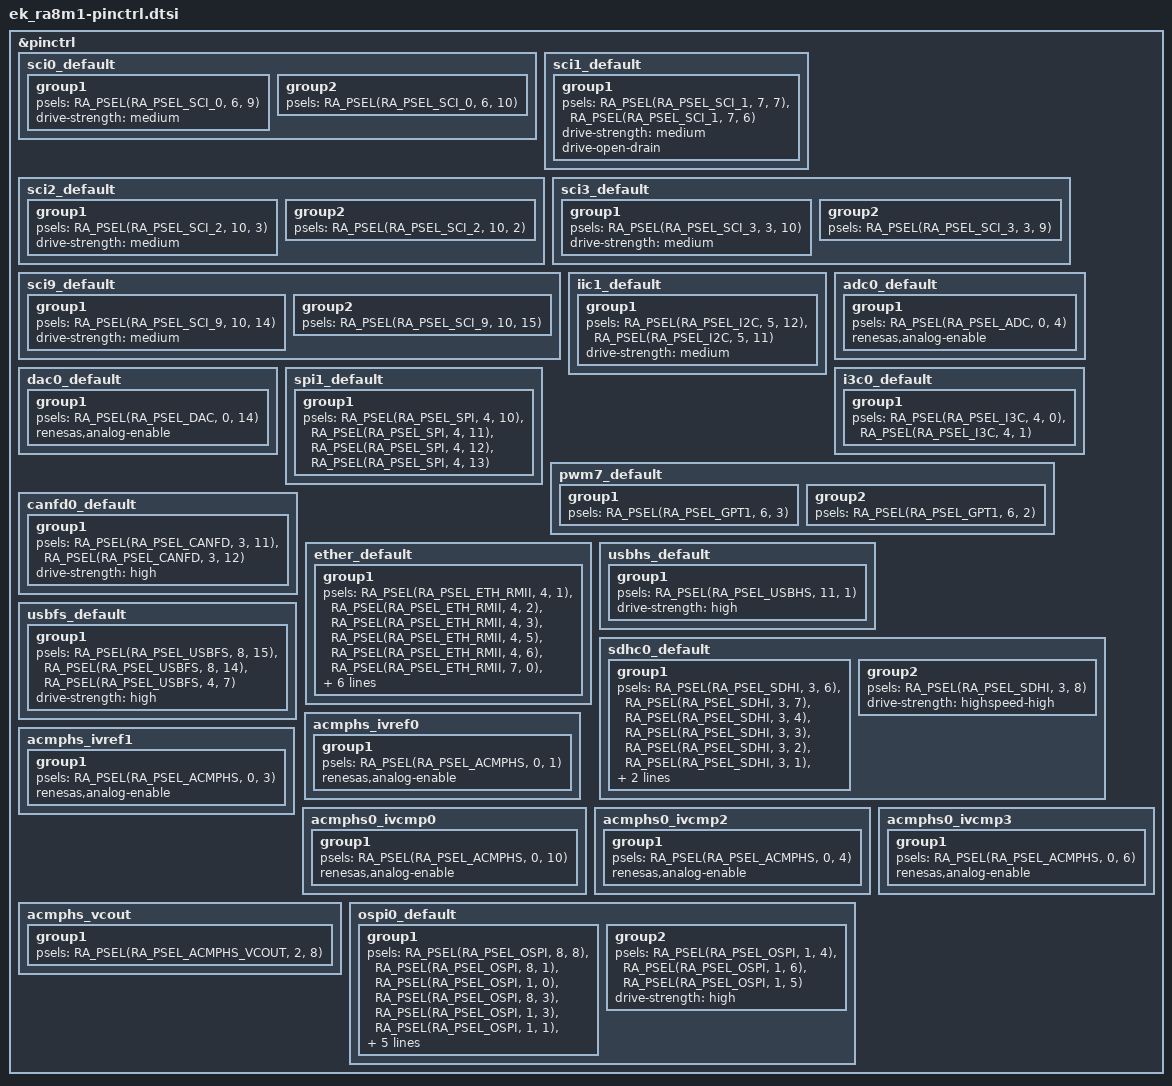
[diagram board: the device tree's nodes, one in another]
/*
 * Copyright (c) 2024-2025 Renesas Electronics Corporation
 * SPDX-License-Identifier: Apache-2.0
 */

&pinctrl {
	sci0_default: sci0_default {
		group1 {
			/* tx */
			psels = <RA_PSEL(RA_PSEL_SCI_0, 6, 9)>;
			drive-strength = "medium";
		};

		group2 {
			/* rx */
			psels = <RA_PSEL(RA_PSEL_SCI_0, 6, 10)>;
		};
	};

	sci1_default: sci1_default {
		group1 {
			/* sda scl */
			psels = <RA_PSEL(RA_PSEL_SCI_1, 7, 7)>, <RA_PSEL(RA_PSEL_SCI_1, 7, 6)>;
			drive-strength = "medium";
			drive-open-drain;
		};
	};

	sci2_default: sci2_default {
		group1 {
			/* tx */
			psels = <RA_PSEL(RA_PSEL_SCI_2, 10, 3)>;
			drive-strength = "medium";
		};

		group2 {
			/* rx */
			psels = <RA_PSEL(RA_PSEL_SCI_2, 10, 2)>;
		};
	};

	sci3_default: sci3_default {
		group1 {
			/* tx */
			psels = <RA_PSEL(RA_PSEL_SCI_3, 3, 10)>;
			drive-strength = "medium";
		};

		group2 {
			/* rx */
			psels = <RA_PSEL(RA_PSEL_SCI_3, 3, 9)>;
		};
	};

	sci9_default: sci9_default {
		group1 {
			/* tx */
			psels = <RA_PSEL(RA_PSEL_SCI_9, 10, 14)>;
			drive-strength = "medium";
		};

		group2 {
			/* rx */
			psels = <RA_PSEL(RA_PSEL_SCI_9, 10, 15)>;
		};
	};

	iic1_default: iic1_default {
		group1 {
			/* SCL1 SDA1*/
			psels = <RA_PSEL(RA_PSEL_I2C, 5, 12)>, <RA_PSEL(RA_PSEL_I2C, 5, 11)>;
			drive-strength = "medium";
		};
	};

	adc0_default: adc0_default {
		group1 {
			/* input */
			psels = <RA_PSEL(RA_PSEL_ADC, 0, 4)>;
			renesas,analog-enable;
		};
	};

	dac0_default: dac0_default {
		group1 {
			/* output */
			psels = <RA_PSEL(RA_PSEL_DAC, 0, 14)>;
			renesas,analog-enable;
		};
	};

	spi1_default: spi1_default {
		group1 {
			/* MISO MOSI RSPCK SSL*/
			psels = <RA_PSEL(RA_PSEL_SPI, 4, 10)>,
				<RA_PSEL(RA_PSEL_SPI, 4, 11)>,
				<RA_PSEL(RA_PSEL_SPI, 4, 12)>,
				<RA_PSEL(RA_PSEL_SPI, 4, 13)>;
		};
	};

	i3c0_default: i3c0_default {
		group1 {
			/* SCL SDA */
			psels = <RA_PSEL(RA_PSEL_I3C, 4, 0)>,
				<RA_PSEL(RA_PSEL_I3C, 4, 1)>;
		};
	};

	pwm7_default: pwm7_default {
		group1 {
			/* GTIOC7A */
			psels = <RA_PSEL(RA_PSEL_GPT1, 6, 3)>;
		};

		group2 {
			/* GTIOC7B */
			psels = <RA_PSEL(RA_PSEL_GPT1, 6, 2)>;
		};
	};

	canfd0_default: canfd0_default {
		group1 {
			/* CRX0 CTX0 */
			psels = <RA_PSEL(RA_PSEL_CANFD, 3, 11)>,
				<RA_PSEL(RA_PSEL_CANFD, 3, 12)>;
			drive-strength = "high";
		};
	};

	ether_default: ether_default {
		group1 {
			psels = <RA_PSEL(RA_PSEL_ETH_RMII, 4, 1)>, /* ET0_MDC */
				<RA_PSEL(RA_PSEL_ETH_RMII, 4, 2)>, /* ET0_MDIO */
				<RA_PSEL(RA_PSEL_ETH_RMII, 4, 3)>, /* ET0_LINKSTA */
				<RA_PSEL(RA_PSEL_ETH_RMII, 4, 5)>, /* RMII0_TXD_EN_B */
				<RA_PSEL(RA_PSEL_ETH_RMII, 4, 6)>, /* RMII0_TXD1_BR */
				<RA_PSEL(RA_PSEL_ETH_RMII, 7, 0)>, /* RMII0_TXD0_B */
				<RA_PSEL(RA_PSEL_ETH_RMII, 7, 1)>, /* REF50CK0_B */
				<RA_PSEL(RA_PSEL_ETH_RMII, 7, 2)>, /* RMII0_RXD0_B */
				<RA_PSEL(RA_PSEL_ETH_RMII, 7, 3)>, /* RMII0_RXD1_B */
				<RA_PSEL(RA_PSEL_ETH_RMII, 7, 4)>, /* RMII0_RX_ER_B */
				<RA_PSEL(RA_PSEL_ETH_RMII, 7, 5)>; /* RMII0_CRS_DV_B */
			drive-strength = "high";
		};
	};

	usbhs_default: usbhs_default {
		group1 {
			psels = <RA_PSEL(RA_PSEL_USBHS, 11, 1)>; /* VBUS */
			drive-strength = "high";
		};
	};

	sdhc0_default: sdhc0_default {
		group1 {
			psels = <RA_PSEL(RA_PSEL_SDHI, 3, 6)>, /* SDCD */
				<RA_PSEL(RA_PSEL_SDHI, 3, 7)>, /* SDCMD */
				<RA_PSEL(RA_PSEL_SDHI, 3, 4)>, /* SDDATA0 */
				<RA_PSEL(RA_PSEL_SDHI, 3, 3)>, /* SDDATA1 */
				<RA_PSEL(RA_PSEL_SDHI, 3, 2)>, /* SDDATA2 */
				<RA_PSEL(RA_PSEL_SDHI, 3, 1)>, /* SDDATA3 */
				<RA_PSEL(RA_PSEL_SDHI, 3, 5)>; /* SDWP */
			drive-strength = "high";
		};

		group2 {
			psels = <RA_PSEL(RA_PSEL_SDHI, 3, 8)>; /* SDCLK */
			drive-strength = "highspeed-high";
		};
	};

	usbfs_default: usbfs_default {
		group1 {
			/* USBP USBN */
			psels = <RA_PSEL(RA_PSEL_USBFS, 8, 15)>,
				<RA_PSEL(RA_PSEL_USBFS, 8, 14)>,
				<RA_PSEL(RA_PSEL_USBFS, 4, 7)>;
			drive-strength = "high";
		};
	};

	/omit-if-no-ref/ acmphs_ivref0: acmphs_ivref0 {
		group1 {
			/* IVREF0 */
			psels = <RA_PSEL(RA_PSEL_ACMPHS, 0, 1)>;
			renesas,analog-enable;
		};
	};

	/omit-if-no-ref/ acmphs_ivref1: acmphs_ivref1 {
		group1 {
			/* IVREF1 */
			psels = <RA_PSEL(RA_PSEL_ACMPHS, 0, 3)>;
			renesas,analog-enable;
		};
	};

	/omit-if-no-ref/ acmphs0_ivcmp0: acmphs0_ivcmp0 {
		group1 {
			/* CH0 IVCMP0 */
			psels = <RA_PSEL(RA_PSEL_ACMPHS, 0, 10)>;
			renesas,analog-enable;
		};
	};

	/omit-if-no-ref/ acmphs0_ivcmp2: acmphs0_ivcmp2 {
		group1 {
			/* CH0 IVCMP2 */
			psels = <RA_PSEL(RA_PSEL_ACMPHS, 0, 4)>;
			renesas,analog-enable;
		};
	};

	/omit-if-no-ref/ acmphs0_ivcmp3: acmphs0_ivcmp3 {
		group1 {
			/* CH0 IVCMP3 */
			psels = <RA_PSEL(RA_PSEL_ACMPHS, 0, 6)>;
			renesas,analog-enable;
		};
	};

	/omit-if-no-ref/ acmphs_vcout: acmphs_vcout {
		group1 {
			/* VCOUT */
			psels = <RA_PSEL(RA_PSEL_ACMPHS_VCOUT, 2, 8)>;
		};
	};

	ospi0_default: ospi0_default {
		group1 {
			/* sclk dqs sio0-7 */
			psels = <RA_PSEL(RA_PSEL_OSPI, 8, 8)>, <RA_PSEL(RA_PSEL_OSPI, 8, 1)>,
				<RA_PSEL(RA_PSEL_OSPI, 1, 0)>, <RA_PSEL(RA_PSEL_OSPI, 8, 3)>,
				<RA_PSEL(RA_PSEL_OSPI, 1, 3)>, <RA_PSEL(RA_PSEL_OSPI, 1, 1)>,
				<RA_PSEL(RA_PSEL_OSPI, 1, 2)>, <RA_PSEL(RA_PSEL_OSPI, 8, 0)>,
				<RA_PSEL(RA_PSEL_OSPI, 8, 2)>, <RA_PSEL(RA_PSEL_OSPI, 8, 4)>;
			drive-strength = "highspeed-high";
		};

		group2 {
			/* cs1 rst ecsint1 */
			psels = <RA_PSEL(RA_PSEL_OSPI, 1, 4)>, <RA_PSEL(RA_PSEL_OSPI, 1, 6)>,
				<RA_PSEL(RA_PSEL_OSPI, 1, 5)>;
			drive-strength = "high";
		};
	};
};
